# f2838x_cpu1_cpu1tocm_ipc_regs register map
Vendor: Texas Instruments
Peripheral module from a debugger description file (folder C2000).
Address unit: 16 bits
Registers are 32-bit, read-write, no defined reset value unless marked. A register's access mark holds for its fields unless they carry their own. Offsets are as the file gives them; lines under a group give offsets from that group; [hi:lo] are bit positions; {n}, {i} and the like mark numbered series; 'fields as' and 'values as' point back to an identical list; <NAME> marks a mode.

## CPU1TOCM_IPC_REGS_CPU1VIEW — CPU1TOCM IPC Registers
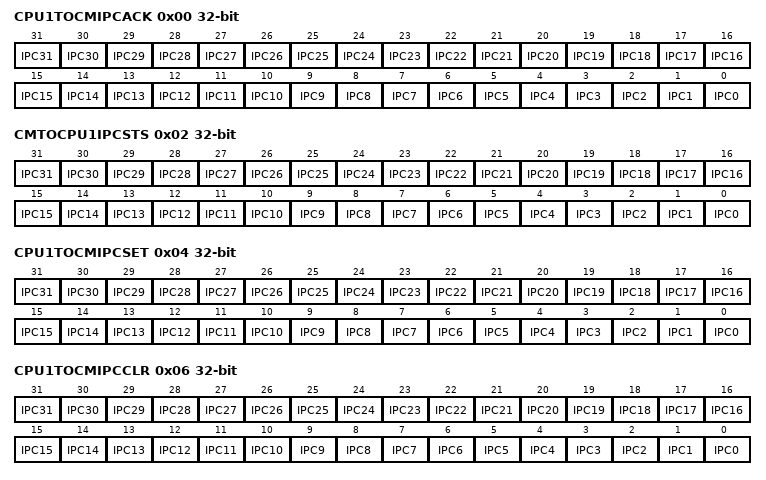
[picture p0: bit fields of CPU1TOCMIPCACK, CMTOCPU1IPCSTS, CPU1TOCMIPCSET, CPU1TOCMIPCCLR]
0x00 CPU1TOCMIPCACK
  [n] IPC{n} (n=0..31) — Acknowledgement from CM to CPU1TOCMIPCFLG.IPC{n} bit
0x02 CMTOCPU1IPCSTS ro
  [n] IPC{n} (n=0..31) — IPC{n} Request from CPU1 to CM
0x04 CPU1TOCMIPCSET
  [n] IPC{n} (n=0..31) — Set CMTOCPU1IPCFLG.IPC{n} Flag
0x06 CPU1TOCMIPCCLR
  [n] IPC{n} (n=0..31) — Clear CMTOCPU1IPCFLG.IPC{n} Flag
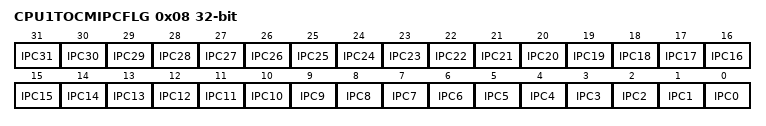
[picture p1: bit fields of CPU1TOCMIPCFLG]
0x08 CPU1TOCMIPCFLG ro
  [n] IPC{n} (n=0..31) — CM to CPU1 IPC{n} Flag Status
0x0C IPCCOUNTERL ro
  [31:0] COUNT — IPC Counter's lower 32-bit
0x0E IPCCOUNTERH ro
  [31:0] COUNT — IPC Counter's upper 32-bit
0x10 CPU1TOCMIPCSENDCOM ro
  [31:0] COMMAND — Refelects the state of CPU1TOCMIPCSENDCOM register
0x12 CPU1TOCMIPCSENDADDR ro
  [31:0] ADDRESS — Refelects the state of CPU1TOCMIPCSENDADDR register
0x14 CPU1TOCMIPCSENDDATA ro
  [31:0] WDATA — Refelects the state of CPU1TOCMIPCSENDDATA register
0x16 CMTOCPU1IPCREPLY
  [31:0] RDATA — CM to CPU1 IPC Reply
0x18 CMTOCPU1IPCRECVCOM
  [31:0] COMMAND — CM to CPU1 IPC Command
0x1A CMTOCPU1IPCRECVADDR
  [31:0] ADDRESS — CM to CPU1 IPC Address
0x1C CMTOCPU1IPCRECVDATA
  [31:0] WDATA — CM to CPU1 IPC Data
0x1E CPU1TOCMIPCREPLY
  [31:0] RDATA — CPU1 to CM IPC Reply
0x20 CMTOCPU1IPCBOOTSTS
  [31:0] BOOTSTS — CM to CPU1 IPC Boot Status
0x22 CPU1TOCMIPCBOOTMODE
  [31:0] BOOTMODE — CPU1 to CM IPC Boot Mode.
